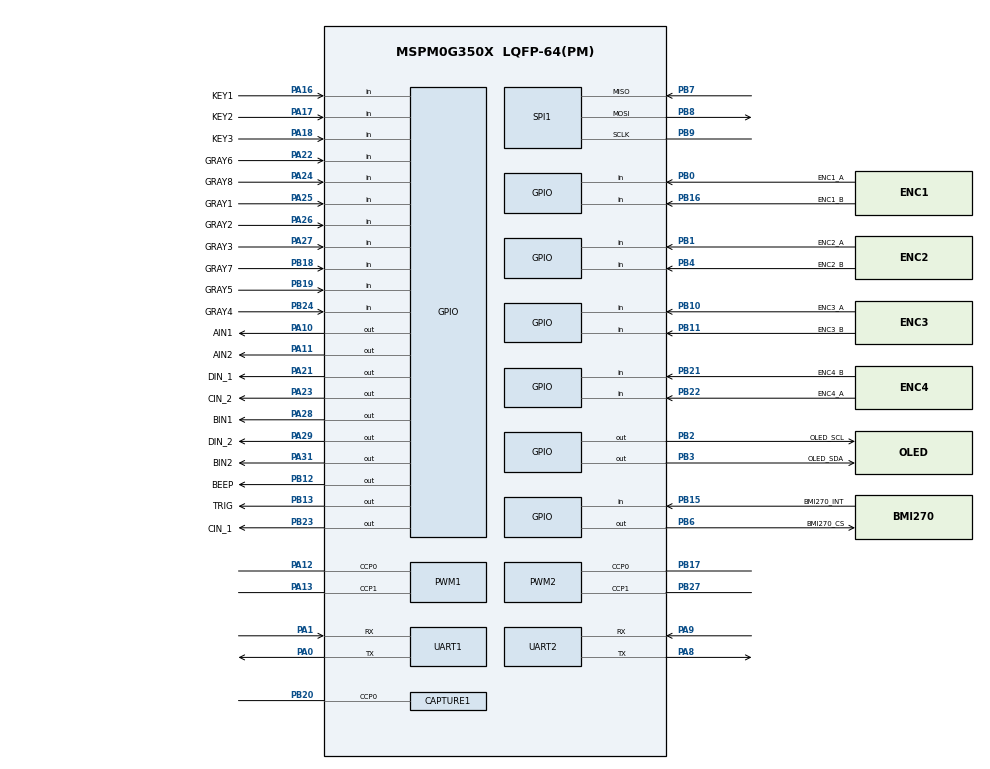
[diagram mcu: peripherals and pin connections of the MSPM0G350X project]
/**
 * @cliArgs --device "MSPM0G350X" --part "Default" --package "LQFP-64(PM)" --product "mspm0_sdk@2.05.01.00"
 * @versions {"tool":"1.24.1+4189"}
 */

/**
 * Import the modules used in this configuration.
 */
const CAPTURE  = scripting.addModule("/ti/driverlib/CAPTURE", {}, false);
const CAPTURE1 = CAPTURE.addInstance();
const GPIO     = scripting.addModule("/ti/driverlib/GPIO", {}, false);
const GPIO1    = GPIO.addInstance();
const GPIO2    = GPIO.addInstance();
const GPIO3    = GPIO.addInstance();
const GPIO4    = GPIO.addInstance();
const GPIO5    = GPIO.addInstance();
const GPIO6    = GPIO.addInstance();
const PWM      = scripting.addModule("/ti/driverlib/PWM", {}, false);
const PWM1     = PWM.addInstance();
const PWM2     = PWM.addInstance();
const SPI      = scripting.addModule("/ti/driverlib/SPI", {}, false);
const SPI1     = SPI.addInstance();
const SYSCTL   = scripting.addModule("/ti/driverlib/SYSCTL");
const TIMER    = scripting.addModule("/ti/driverlib/TIMER", {}, false);
const TIMER1   = TIMER.addInstance();
const UART     = scripting.addModule("/ti/driverlib/UART", {}, false);
const UART1    = UART.addInstance();
const UART2    = UART.addInstance();

/**
 * Write custom configuration values to the imported modules.
 */
const divider7       = system.clockTree["PLL_PDIV"];
divider7.divideValue = 2;

const divider9       = system.clockTree["UDIV"];
divider9.divideValue = 2;

const multiplier2         = system.clockTree["PLL_QDIV"];
multiplier2.multiplyValue = 10;

const mux8       = system.clockTree["HSCLKMUX"];
mux8.inputSelect = "HSCLKMUX_SYSPLL0";

CAPTURE1.$name                              = "CAPTURE_ECHO";
CAPTURE1.timerClkDiv                        = 8;
CAPTURE1.timerPeriod                        = "60 ms";
CAPTURE1.timerStartTimer                    = true;
CAPTURE1.captEdgeDetection                  = "EDGE";
CAPTURE1.interrupts                         = ["CC0_DN"];
CAPTURE1.peripheral.$assign                 = "TIMG12";
CAPTURE1.peripheral.ccp0Pin.$assign         = "PB20";
CAPTURE1.ccp0PinConfig.hideOutputInversion  = scripting.forceWrite(false);
CAPTURE1.ccp0PinConfig.onlyInternalResistor = scripting.forceWrite(false);
CAPTURE1.ccp0PinConfig.passedPeripheralType = scripting.forceWrite("Digital");
CAPTURE1.ccp0PinConfig.$name                = "ti_driverlib_gpio_GPIOPinGeneric8";

const Board = scripting.addModule("/ti/driverlib/Board", {}, false);

GPIO1.$name                              = "GPIO_OUTPUT";
GPIO1.associatedPins.create(12);
GPIO1.associatedPins[0].$name            = "AIN1";
GPIO1.associatedPins[0].assignedPort     = "PORTA";
GPIO1.associatedPins[0].pin.$assign      = "PA10";
GPIO1.associatedPins[1].$name            = "AIN2";
GPIO1.associatedPins[1].assignedPort     = "PORTA";
GPIO1.associatedPins[1].pin.$assign      = "PA11";
GPIO1.associatedPins[2].assignedPort     = "PORTB";
GPIO1.associatedPins[2].$name            = "LED1";
GPIO1.associatedPins[3].$name            = "BIN1";
GPIO1.associatedPins[3].assignedPort     = "PORTA";
GPIO1.associatedPins[3].pin.$assign      = "PA28";
GPIO1.associatedPins[4].$name            = "BIN2";
GPIO1.associatedPins[4].pin.$assign      = "PA31";
GPIO1.associatedPins[5].$name            = "TRIG";
GPIO1.associatedPins[5].pin.$assign      = "PB13";
GPIO1.associatedPins[6].$name            = "BEEP";
GPIO1.associatedPins[6].assignedPort     = "PORTB";
GPIO1.associatedPins[6].internalResistor = "PULL_UP";
GPIO1.associatedPins[6].pin.$assign      = "PB12";
GPIO1.associatedPins[7].$name            = "LED2";
GPIO1.associatedPins[7].internalResistor = "PULL_UP";
GPIO1.associatedPins[8].$name            = "CIN_1";
GPIO1.associatedPins[8].pin.$assign      = "PB23";
GPIO1.associatedPins[9].$name            = "CIN_2";
GPIO1.associatedPins[9].pin.$assign      = "PA23";
GPIO1.associatedPins[10].$name           = "DIN_1";
GPIO1.associatedPins[10].pin.$assign     = "PA21";
GPIO1.associatedPins[11].$name           = "DIN_2";
GPIO1.associatedPins[11].pin.$assign     = "PA29";

GPIO2.$name                          = "GPIO_ENCODER";
GPIO2.associatedPins.create(8);
GPIO2.associatedPins[0].direction    = "INPUT";
GPIO2.associatedPins[0].interruptEn  = true;
GPIO2.associatedPins[0].polarity     = "RISE_FALL";
GPIO2.associatedPins[0].$name        = "ENC1_A";
GPIO2.associatedPins[0].pin.$assign  = "PB0";
GPIO2.associatedPins[1].direction    = "INPUT";
GPIO2.associatedPins[1].$name        = "ENC1_B";
GPIO2.associatedPins[1].interruptEn  = true;
GPIO2.associatedPins[1].polarity     = "RISE_FALL";
GPIO2.associatedPins[1].pin.$assign  = "PB16";
GPIO2.associatedPins[2].direction    = "INPUT";
GPIO2.associatedPins[2].$name        = "ENC2_A";
GPIO2.associatedPins[2].assignedPort = "PORTB";
GPIO2.associatedPins[2].interruptEn  = true;
GPIO2.associatedPins[2].polarity     = "RISE_FALL";
GPIO2.associatedPins[2].pin.$assign  = "PB1";
GPIO2.associatedPins[3].direction    = "INPUT";
GPIO2.associatedPins[3].$name        = "ENC2_B";
GPIO2.associatedPins[3].interruptEn  = true;
GPIO2.associatedPins[3].polarity     = "RISE_FALL";
GPIO2.associatedPins[3].pin.$assign  = "PB4";
GPIO2.associatedPins[4].$name        = "ENC3_A";
GPIO2.associatedPins[4].direction    = "INPUT";
GPIO2.associatedPins[4].interruptEn  = true;
GPIO2.associatedPins[4].polarity     = "RISE_FALL";
GPIO2.associatedPins[4].pin.$assign  = "PB10";
GPIO2.associatedPins[5].$name        = "ENC3_B";
GPIO2.associatedPins[5].direction    = "INPUT";
GPIO2.associatedPins[5].interruptEn  = true;
GPIO2.associatedPins[5].polarity     = "RISE_FALL";
GPIO2.associatedPins[5].pin.$assign  = "PB11";
GPIO2.associatedPins[6].$name        = "ENC4_A";
GPIO2.associatedPins[6].direction    = "INPUT";
GPIO2.associatedPins[6].interruptEn  = true;
GPIO2.associatedPins[6].polarity     = "RISE_FALL";
GPIO2.associatedPins[6].pin.$assign  = "PB22";
GPIO2.associatedPins[7].$name        = "ENC4_B";
GPIO2.associatedPins[7].direction    = "INPUT";
GPIO2.associatedPins[7].interruptEn  = true;
GPIO2.associatedPins[7].polarity     = "RISE_FALL";
GPIO2.associatedPins[7].pin.$assign  = "PB21";

GPIO3.$name                         = "GPIO_GRAY";
GPIO3.associatedPins.create(8);
GPIO3.associatedPins[0].$name       = "GRAY1";
GPIO3.associatedPins[0].direction   = "INPUT";
GPIO3.associatedPins[0].pin.$assign = "PA25";
GPIO3.associatedPins[1].$name       = "GRAY2";
GPIO3.associatedPins[1].direction   = "INPUT";
GPIO3.associatedPins[1].pin.$assign = "PA26";
GPIO3.associatedPins[2].$name       = "GRAY3";
GPIO3.associatedPins[2].direction   = "INPUT";
GPIO3.associatedPins[2].pin.$assign = "PA27";
GPIO3.associatedPins[3].$name       = "GRAY4";
GPIO3.associatedPins[3].direction   = "INPUT";
GPIO3.associatedPins[3].pin.$assign = "PB24";
GPIO3.associatedPins[4].$name       = "GRAY5";
GPIO3.associatedPins[4].direction   = "INPUT";
GPIO3.associatedPins[4].pin.$assign = "PB19";
GPIO3.associatedPins[5].$name       = "GRAY6";
GPIO3.associatedPins[5].direction   = "INPUT";
GPIO3.associatedPins[5].pin.$assign = "PA22";
GPIO3.associatedPins[6].$name       = "GRAY7";
GPIO3.associatedPins[6].direction   = "INPUT";
GPIO3.associatedPins[6].pin.$assign = "PB18";
GPIO3.associatedPins[7].$name       = "GRAY8";
GPIO3.associatedPins[7].direction   = "INPUT";
GPIO3.associatedPins[7].pin.$assign = "PA24";

GPIO4.$name                                 = "GPIO_KEY";
GPIO4.associatedPins.create(3);
GPIO4.associatedPins[0].$name               = "KEY1";
GPIO4.associatedPins[0].direction           = "INPUT";
GPIO4.associatedPins[0].interruptEn         = true;
GPIO4.associatedPins[0].polarity            = "FALL";
GPIO4.associatedPins[0].assignedPortSegment = "Upper";
GPIO4.associatedPins[0].internalResistor    = "PULL_UP";
GPIO4.associatedPins[0].pin.$assign         = "PA16";
GPIO4.associatedPins[1].assignedPortSegment = "Upper";
GPIO4.associatedPins[1].direction           = "INPUT";
GPIO4.associatedPins[1].interruptEn         = true;
GPIO4.associatedPins[1].polarity            = "FALL";
GPIO4.associatedPins[1].$name               = "KEY2";
GPIO4.associatedPins[1].internalResistor    = "PULL_UP";
GPIO4.associatedPins[1].pin.$assign         = "PA17";
GPIO4.associatedPins[2].assignedPortSegment = "Upper";
GPIO4.associatedPins[2].$name               = "KEY3";
GPIO4.associatedPins[2].direction           = "INPUT";
GPIO4.associatedPins[2].interruptEn         = true;
GPIO4.associatedPins[2].polarity            = "FALL";
GPIO4.associatedPins[2].internalResistor    = "PULL_UP";
GPIO4.associatedPins[2].pin.$assign         = "PA18";

GPIO5.$name                          = "GPIO_OLED";
GPIO5.associatedPins.create(2);
GPIO5.associatedPins[0].$name        = "OLED_SCL";
GPIO5.associatedPins[0].assignedPort = "PORTB";
GPIO5.associatedPins[0].initialValue = "SET";
GPIO5.associatedPins[0].pin.$assign  = "PB2";
GPIO5.associatedPins[1].$name        = "OLED_SDA";
GPIO5.associatedPins[1].initialValue = "SET";
GPIO5.associatedPins[1].pin.$assign  = "PB3";

GPIO6.$name                          = "GPIO_BMI270";
GPIO6.associatedPins.create(2);
GPIO6.associatedPins[0].$name        = "BMI270_INT";
GPIO6.associatedPins[0].direction    = "INPUT";
GPIO6.associatedPins[0].polarity     = "RISE";
GPIO6.associatedPins[0].pin.$assign  = "PB15";
GPIO6.associatedPins[1].$name        = "BMI270_CS";
GPIO6.associatedPins[1].initialValue = "SET";
GPIO6.associatedPins[1].pin.$assign  = "PB6";

PWM1.$name                      = "PWM_0";
PWM1.timerStartTimer            = true;
PWM1.pwmMode                    = "EDGE_ALIGN_UP";
PWM1.timerCount                 = 4000;
PWM1.peripheral.ccp0Pin.$assign = "PA12";
PWM1.peripheral.ccp1Pin.$assign = "PA13";
PWM1.PWM_CHANNEL_0.$name        = "ti_driverlib_pwm_PWMTimerCC0";
PWM1.PWM_CHANNEL_1.$name        = "ti_driverlib_pwm_PWMTimerCC1";
PWM1.ccp0PinConfig.$name        = "ti_driverlib_gpio_GPIOPinGeneric6";
PWM1.ccp1PinConfig.$name        = "ti_driverlib_gpio_GPIOPinGeneric7";

PWM2.$name                      = "PWM_1";
PWM2.peripheral.$assign         = "TIMA1";
PWM2.peripheral.ccp0Pin.$assign = "PB17";
PWM2.peripheral.ccp1Pin.$assign = "PB27";
PWM2.PWM_CHANNEL_0.$name        = "ti_driverlib_pwm_PWMTimerCC2";
PWM2.PWM_CHANNEL_1.$name        = "ti_driverlib_pwm_PWMTimerCC3";
PWM2.ccp0PinConfig.$name        = "ti_driverlib_gpio_GPIOPinGeneric11";
PWM2.ccp1PinConfig.$name        = "ti_driverlib_gpio_GPIOPinGeneric12";

SPI1.$name                      = "SPI_0";
SPI1.targetBitRate              = 5000000;
SPI1.peripheral.sclkPin.$assign = "PB9";
SPI1.peripheral.mosiPin.$assign = "PB8";
SPI1.peripheral.misoPin.$assign = "PB7";
SPI1.sclkPinConfig.$name        = "ti_driverlib_gpio_GPIOPinGeneric0";
SPI1.mosiPinConfig.$name        = "ti_driverlib_gpio_GPIOPinGeneric1";
SPI1.misoPinConfig.$name        = "ti_driverlib_gpio_GPIOPinGeneric2";
SPI1.cs0PinConfig.$name         = "ti_driverlib_gpio_GPIOPinGeneric3";

SYSCTL.MCLKSource            = "HSCLK";
SYSCTL.forceDefaultClkConfig = true;
SYSCTL.SYSPLL_CLK0En         = true;
SYSCTL.clockTreeEn           = true;

TIMER1.$name              = "TIMER_0";
TIMER1.timerClkDiv        = 8;
TIMER1.timerPeriod        = "10 ms";
TIMER1.timerStartTimer    = true;
TIMER1.interrupts         = ["ZERO"];
TIMER1.timerClkPrescale   = 2;
TIMER1.timerMode          = "PERIODIC";
TIMER1.peripheral.$assign = "TIMG6";

UART1.$name                    = "UART_0";
UART1.targetBaudRate           = 115200;
UART1.peripheral.rxPin.$assign = "PA1";
UART1.peripheral.txPin.$assign = "PA0";
UART1.txPinConfig.$name        = "ti_driverlib_gpio_GPIOPinGeneric4";
UART1.rxPinConfig.$name        = "ti_driverlib_gpio_GPIOPinGeneric5";

UART2.$name                    = "UART_1";
UART2.targetBaudRate           = 115200;
UART2.peripheral.rxPin.$assign = "PA9";
UART2.peripheral.txPin.$assign = "PA8";
UART2.txPinConfig.$name        = "ti_driverlib_gpio_GPIOPinGeneric9";
UART2.rxPinConfig.$name        = "ti_driverlib_gpio_GPIOPinGeneric10";

/**
 * Pinmux solution for unlocked pins/peripherals. This ensures that minor changes to the automatic solver in a future
 * version of the tool will not impact the pinmux you originally saw.  These lines can be completely deleted in order to
 * re-solve from scratch.
 */
Board.peripheral.$suggestSolution            = "DEBUGSS";
Board.peripheral.swclkPin.$suggestSolution   = "PA20";
Board.peripheral.swdioPin.$suggestSolution   = "PA19";
GPIO1.associatedPins[2].pin.$suggestSolution = "PB14";
GPIO1.associatedPins[7].pin.$suggestSolution = "PA14";
PWM1.peripheral.$suggestSolution             = "TIMG0";
SPI1.peripheral.$suggestSolution             = "SPI1";
SPI1.peripheral.cs0Pin.$suggestSolution      = "PA2";
UART1.peripheral.$suggestSolution            = "UART0";
UART2.peripheral.$suggestSolution            = "UART1";
